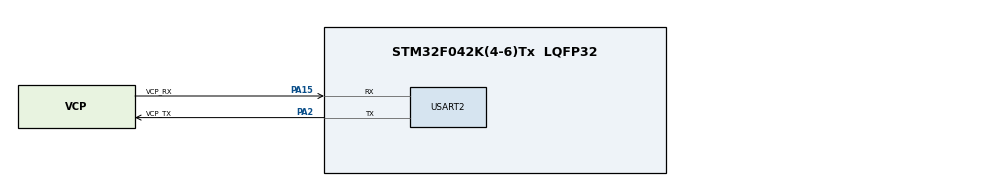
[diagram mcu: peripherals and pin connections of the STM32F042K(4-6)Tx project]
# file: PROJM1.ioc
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Mcu.Family=STM32F0
Mcu.Name=STM32F042K(4-6)Tx
Mcu.Package=LQFP32
PA13.GPIO_Label=SWDIO
PA13.Mode=Serial_Wire
PA13.Signal=SYS_SWDIO
PA14.GPIO_Label=SWCLK
PA14.Mode=Serial_Wire
PA14.Signal=SYS_SWCLK
PA15.GPIO_Label=VCP_RX
PA15.Mode=Asynchronous
PA15.Signal=USART2_RX
PA2.GPIO_Label=VCP_TX
PA2.Mode=Asynchronous
PA2.Signal=USART2_TX
PF0-OSC_IN.GPIO_Label=MCO
PF0-OSC_IN.Mode=HSE-External-Clock-Source
PF0-OSC_IN.Signal=RCC_OSC_IN
ProjectManager.HeapSize=0x200
ProjectManager.StackSize=0x400
ProjectManager.TargetToolchain=STM32CubeIDE
USART2.VirtualMode-Asynchronous=VM_ASYNC
board=NUCLEO-F042K6

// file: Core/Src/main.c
/* USER CODE BEGIN Header */
/**
  ******************************************************************************
  * @file           : main.c
  * @brief          : Main program body
  ******************************************************************************
  * @attention
  *
  * Copyright (c) 2023 STMicroelectronics.
  * All rights reserved.
  *
  * This software is licensed under terms that can be found in the LICENSE file
  * in the root directory of this software component.
  * If no LICENSE file comes with this software, it is provided AS-IS.
  *
  ******************************************************************************
  */
/* USER CODE END Header */
#include "main.h"

UART_HandleTypeDef huart2;

void SystemClock_Config(void);
static void MX_GPIO_Init(void);
static void MX_USART2_UART_Init(void);

int main(void)
{

  /* MCU Configuration--------------------------------------------------------*/

  /* Reset of all peripherals, Initializes the Flash interface and the Systick. */
  HAL_Init();

  /* Configure the system clock */
  SystemClock_Config();

  /* Initialize all configured peripherals */
  MX_GPIO_Init();
  MX_USART2_UART_Init();
  /* USER CODE BEGIN 2 */

  uint8_t roundkeys[AES_ROUND_KEY_SIZE];
  uint8_t xor_key[16] = { 0x76, 0x38, 0x79, 0x2F, 0x42, 0x3F, 0x45, 0x28, 0x48, 0x2B, 0x4B, 0x62, 0x50, 0x65, 0x53, 0x68};
  uint64_t DES_key = 0x5A72347537782141;
  uint8_t AES_key[16] = { 0x2F, 0x42, 0x3F, 0x45, 0x28, 0x48, 0x2B, 0x4D, 0x62, 0x51, 0x65, 0x54, 0x68, 0x57, 0x6D, 0x5A};

//  uint8_t *w;
//  w = aes_init(sizeof(AES_key));

  /* USER CODE END 2 */

  /* Infinite loop */
  /* USER CODE BEGIN WHILE */
  while (1)
  {
	uint8_t input_array[17] = { 0x00,  0x00, 0x00, 0x00, 0x00, 0x00, 0x00, 0x00, 0x00, 0x00, 0x00, 0x00, 0x00, 0x00, 0x00, 0x00, 0x00};
	uint8_t output_array[17] = { 0x00,  0x00, 0x00, 0x00, 0x00, 0x00, 0x00, 0x00, 0x00, 0x00, 0x00, 0x00, 0x00, 0x00, 0x00, 0x00, 0x00};
	uint8_t ciphertext [16] = {0x00,  0x00, 0x00, 0x00, 0x00, 0x00, 0x00, 0x00, 0x00, 0x00, 0x00, 0x00, 0x00, 0x00, 0x00, 0x00};
	uint8_t plaintext[16] ={0x00,  0x00, 0x00, 0x00, 0x00, 0x00, 0x00, 0x00, 0x00, 0x00, 0x00, 0x00, 0x00, 0x00, 0x00, 0x00};

	uint64_t des_in1 = 0;
	uint64_t des_in2 = 0;
	uint64_t des_out1 = 0;
	uint64_t des_out2 = 0;

	  HAL_UART_Receive(&huart2, input_array, 17, HAL_MAX_DELAY);

	  for(int i = 0; i<16; i++){
		  ciphertext[i] = input_array[i+1];
	  }

	  switch (input_array[0]){
	  	  case 0x10:
			  for(int i = 0; i<16; i++){
				  plaintext[i] = input_array[i+1];
			  }
	  		  break;
	  	  case 0x20:
	  		  do_xor(ciphertext, xor_key, plaintext);
	  	  break;

	  	  case 0x30:
	  		// First input handles bytes 0-7 (LSBytes)
			for(int i = 0; i < 8; i++) des_in1 |= ((uint64_t)ciphertext[15-i] << (i*8));

			// First input handles bytes 8-15 (MSBytes)
			for(int i = 0; i < 8; i++) des_in2 |= ((uint64_t)ciphertext[7-i] << (i*8));

			des_out1 = des_decrypt(des_in1, DES_key);
			des_out2 = des_decrypt(des_in2, DES_key);

			for(int i = 0; i < 8; i ++){
				plaintext[15 - i] = (uint8_t)((des_out1 >> (8 * i)) & 0xFF);
				plaintext[7 - i] = (uint8_t)((des_out2 >> (8 * i)) & 0xFF);
			}
	  		  break;

	  	  case 0x40:
	  		aes_key_schedule_128(AES_key, roundkeys);
	  		aes_decrypt_128(roundkeys, ciphertext, plaintext);

	  	  break;
	  }

	  // Check success byte
	  if(plaintext[0] == 0xFE){
		  output_array[0] = 0x00; // Success
	  } else {
		  output_array[0] = 0x01; // Fail
	  }

	  // Set output array
	  for(int i = 0; i<16; i++){
		  output_array[i+1] = plaintext[i];
	  }

	  HAL_UART_Transmit(&huart2, output_array, 17, HAL_MAX_DELAY);
    /* USER CODE END WHILE */

  }
}

void SystemClock_Config(void)
{
  RCC_OscInitTypeDef RCC_OscInitStruct = {0};
  RCC_ClkInitTypeDef RCC_ClkInitStruct = {0};

  /** Initializes the RCC Oscillators according to the specified parameters
  * in the RCC_OscInitTypeDef structure.
  */
  RCC_OscInitStruct.OscillatorType = RCC_OSCILLATORTYPE_HSI;
  RCC_OscInitStruct.HSIState = RCC_HSI_ON;
  RCC_OscInitStruct.HSICalibrationValue = RCC_HSICALIBRATION_DEFAULT;
  RCC_OscInitStruct.PLL.PLLState = RCC_PLL_NONE;
  if (HAL_RCC_OscConfig(&RCC_OscInitStruct) != HAL_OK)
  {
    Error_Handler();
  }

  /** Initializes the CPU, AHB and APB buses clocks
  */
  RCC_ClkInitStruct.ClockType = RCC_CLOCKTYPE_HCLK|RCC_CLOCKTYPE_SYSCLK
                              |RCC_CLOCKTYPE_PCLK1;
  RCC_ClkInitStruct.SYSCLKSource = RCC_SYSCLKSOURCE_HSI;
  RCC_ClkInitStruct.AHBCLKDivider = RCC_SYSCLK_DIV1;
  RCC_ClkInitStruct.APB1CLKDivider = RCC_HCLK_DIV1;

  if (HAL_RCC_ClockConfig(&RCC_ClkInitStruct, FLASH_LATENCY_0) != HAL_OK)
  {
    Error_Handler();
  }
}

static void MX_USART2_UART_Init(void)
{

  huart2.Instance = USART2;
  huart2.Init.BaudRate = 38400;
  huart2.Init.WordLength = UART_WORDLENGTH_8B;
  huart2.Init.StopBits = UART_STOPBITS_1;
  huart2.Init.Parity = UART_PARITY_NONE;
  huart2.Init.Mode = UART_MODE_TX_RX;
  huart2.Init.HwFlowCtl = UART_HWCONTROL_NONE;
  huart2.Init.OverSampling = UART_OVERSAMPLING_16;
  huart2.Init.OneBitSampling = UART_ONE_BIT_SAMPLE_DISABLE;
  huart2.AdvancedInit.AdvFeatureInit = UART_ADVFEATURE_NO_INIT;
  if (HAL_UART_Init(&huart2) != HAL_OK)
  {
    Error_Handler();
  }

}

static void MX_GPIO_Init(void)
{

  /* GPIO Ports Clock Enable */
  __HAL_RCC_GPIOF_CLK_ENABLE();
  __HAL_RCC_GPIOA_CLK_ENABLE();

}

void Error_Handler(void)
{
  __disable_irq();
  while (1)
  {
  }
}
